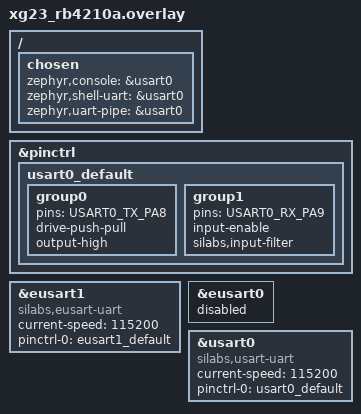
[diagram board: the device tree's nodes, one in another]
/*
 * Copyright (c) 2025, Silicon Laboratories Inc.
 *
 * SPDX-License-Identifier: Apache-2.0
 */

/*
 * Connect EXP4 (PC0) and EXP6 (PC1) of the Expansion Pin header
 */
/ {
	chosen {
		zephyr,console = &usart0;
		zephyr,shell-uart = &usart0;
		zephyr,uart-pipe = &usart0;
	};
};

&pinctrl {
	usart0_default: usart0_default {
		group0 {
			pins = <USART0_TX_PA8>;
			drive-push-pull;
			output-high;
		};

		group1 {
			pins = <USART0_RX_PA9>;
			input-enable;
			silabs,input-filter;
		};
	};
};

dut: &eusart1 {
	compatible = "silabs,eusart-uart";
	current-speed = <115200>;
	pinctrl-0 = <&eusart1_default>;
	pinctrl-names = "default";
	status = "okay";
	/delete-property/ cs-gpios;
};

&eusart0 {
	status = "disabled";
};

&usart0 {
	compatible = "silabs,usart-uart";
	current-speed = <115200>;
	pinctrl-0 = <&usart0_default>;
	pinctrl-names = "default";
	status = "okay";
};
